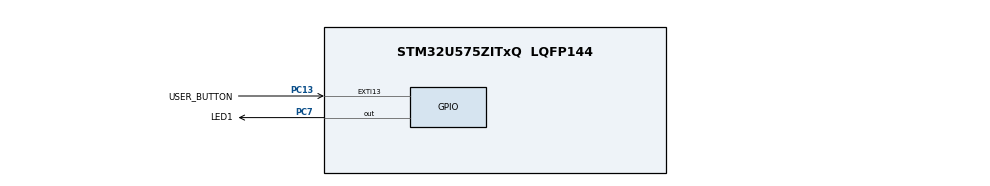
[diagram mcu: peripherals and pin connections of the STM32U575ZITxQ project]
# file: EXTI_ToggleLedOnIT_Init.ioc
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CORTEX_M33_NS.userName=CORTEX_M33
Mcu.Family=STM32U5
Mcu.Name=STM32U575ZITxQ
Mcu.Package=LQFP144
NVIC.EXTI13_IRQn=true\:0\:0\:false\:false\:true\:true\:true\:true
NVIC.PriorityGroup=NVIC_PRIORITYGROUP_4
PC13.GPIO_Label=USER_BUTTON
PC13.GPIO_ModeDefaultEXTI=GPIO_MODE_IT_FALLING
PC13.Signal=GPXTI13
PC7.GPIO_Label=LED1
PC7.Signal=GPIO_Output
PWR.PowerMode=PWR_SMPS_SUPPLY
ProjectManager.HeapSize=0x200
ProjectManager.StackSize=0x400
ProjectManager.TargetToolchain=EWARM V8.50
RCC.ADCFreq_Value=16000000
RCC.AHBFreq_Value=160000000
RCC.APB1Freq_Value=160000000
RCC.APB1TimFreq_Value=160000000
RCC.APB2Freq_Value=160000000
RCC.APB2TimFreq_Value=160000000
RCC.APB3Freq_Value=160000000
RCC.CortexFreq_Value=160000000
RCC.DACCLockSelectionVirtual=RCC_DAC1CLKSOURCE_LSI
RCC.DACCLockSelectionVirtualString=RCC_DAC1CLKSOURCE_LSI
RCC.EPOD_VALUE=4000000
RCC.HCLKFreq_Value=160000000
RCC.HSE_VALUE=16000000
RCC.HSI48_VALUE=48000000
RCC.HSI_VALUE=16000000
RCC.LSE_VALUE=32768
RCC.LSIDIV_VALUE=32000
RCC.MSI_VALUE=4000000
RCC.PLLN=80
RCC.SYSCLKFreq_VALUE=160000000
RCC.SYSCLKSource=RCC_SYSCLKSOURCE_PLLCLK
RCC.USBFreq_Value=48000000
RCC.VCOOutputFreq_Value=320000000
VP_ICACHE_VS_ICACHE.Mode=DirectMappedCache
VP_LPBAMQUEUE_VS_QUEUE.Mode=QUEUEMODE
VP_LPBAM_VS_SIG1.Mode=SmartRun
VP_LPBAM_VS_SIG4.Mode=LPDMA1
VP_PWR_VS_DBSignals.Mode=DisableDeadBatterySignals
VP_PWR_VS_LPOM.Mode=PowerOptimisation
VP_PWR_VS_SECSignals.Mode=Security/Privilege
board=custom

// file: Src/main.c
/* USER CODE BEGIN Header */
/**
  ******************************************************************************
  * @file    Examples_LL/EXTI/EXTI_ToggleLedOnIT_Init/Src/main.c
  * @author  MCD Application Team
  * @brief   This example describes how to configure the EXTI and use
  *          GPIOs using the STM32U5xx LL API to toggles the available
  *          users Leds on the board when User button is pressed.
  *          Peripheral initialization done using LL initialization function.
  ******************************************************************************
  * @attention
  *
  * Copyright (c) 2021 STMicroelectronics.
  * All rights reserved.
  *
  * This software is licensed under terms that can be found in the LICENSE file
  * in the root directory of this software component.
  * If no LICENSE file comes with this software, it is provided AS-IS.
  *
  ******************************************************************************
  */
/* USER CODE END Header */
#include "main.h"

void SystemClock_Config(void);
static void SystemPower_Config(void);
static void MX_GPIO_Init(void);
static void MX_ICACHE_Init(void);

int main(void)
{

  /* MCU Configuration--------------------------------------------------------*/

  /* Reset of all peripherals, Initializes the Flash interface and the Systick. */

  /* System interrupt init*/
  NVIC_SetPriorityGrouping(NVIC_PRIORITYGROUP_4);

  /* Enable PWR clock interface */

  LL_AHB3_GRP1_EnableClock(LL_AHB3_GRP1_PERIPH_PWR);

  /* Configure the System Power */
  SystemPower_Config();

  /* Configure the system clock */
  SystemClock_Config();

  /* Initialize all configured peripherals */
  MX_GPIO_Init();
  MX_ICACHE_Init();

  /* Infinite loop */
  while (1)
  {

  }
}

void SystemClock_Config(void)
{
  LL_FLASH_SetLatency(LL_FLASH_LATENCY_4);
  while(LL_FLASH_GetLatency()!= LL_FLASH_LATENCY_4)
  {
  }

  LL_PWR_SetRegulVoltageScaling(LL_PWR_REGU_VOLTAGE_SCALE1);
  while (LL_PWR_IsActiveFlag_VOS() == 0)
  {
  }
  LL_RCC_MSIS_Enable();

   /* Wait till MSIS is ready */
  while(LL_RCC_MSIS_IsReady() != 1)
  {
  }

  LL_RCC_MSI_EnableRangeSelection();
  LL_RCC_MSIS_SetRange(LL_RCC_MSISRANGE_4);
  LL_RCC_MSI_SetCalibTrimming(16, LL_RCC_MSI_OSCILLATOR_1);
  LL_RCC_PLL1_ConfigDomain_SYS(LL_RCC_PLL1SOURCE_MSIS, 1, 80, 2);
  LL_RCC_PLL1_EnableDomain_SYS();
  LL_RCC_SetPll1EPodPrescaler(LL_RCC_PLL1MBOOST_DIV_1);
  LL_RCC_PLL1_SetVCOInputRange(LL_RCC_PLLINPUTRANGE_4_8);
  LL_RCC_PLL1_Enable();

   /* Wait till PLL is ready */
  while(LL_RCC_PLL1_IsReady() != 1)
  {
  }

   /* Intermediate AHB prescaler 2 when target frequency clock is higher than 80 MHz */
  LL_RCC_SetAHBPrescaler(LL_RCC_SYSCLK_DIV_2);

  LL_RCC_SetSysClkSource(LL_RCC_SYS_CLKSOURCE_PLL1);

   /* Wait till System clock is ready */
  while(LL_RCC_GetSysClkSource() != LL_RCC_SYS_CLKSOURCE_STATUS_PLL1)
  {
  }

  /* Insure 1us transition state at intermediate medium speed clock*/
  for (__IO uint32_t i = (160 >> 1); i !=0; i--);

  LL_RCC_SetAHBPrescaler(LL_RCC_SYSCLK_DIV_1);
  LL_RCC_SetAPB1Prescaler(LL_RCC_APB1_DIV_1);
  LL_RCC_SetAPB2Prescaler(LL_RCC_APB2_DIV_1);
  LL_RCC_SetAPB3Prescaler(LL_RCC_APB3_DIV_1);

  LL_Init1msTick(160000000);

  LL_SetSystemCoreClock(160000000);
}

/**
  * @brief Power Configuration
  * @retval None
  */
static void SystemPower_Config(void)
{

  /*
   * Disable the internal Pull-Up in Dead Battery pins of UCPD peripheral
   */
  LL_PWR_DisableUCPDDeadBattery();

  /*
   * Switch to SMPS regulator instead of LDO
   */
  LL_PWR_SetRegulatorSupply(LL_PWR_SMPS_SUPPLY);

  while(LL_PWR_IsActiveFlag_REGULATOR()!=1)
  {
  }
}

static void MX_ICACHE_Init(void)
{

  /** Enable instruction cache in 1-way (direct mapped cache)
  */
  LL_ICACHE_SetMode(LL_ICACHE_1WAY);
  LL_ICACHE_Enable();

}

static void MX_GPIO_Init(void)
{
  LL_EXTI_InitTypeDef EXTI_InitStruct = {0};
  LL_GPIO_InitTypeDef GPIO_InitStruct = {0};

  /* GPIO Ports Clock Enable */
  LL_AHB2_GRP1_EnableClock(LL_AHB2_GRP1_PERIPH_GPIOC);

  /**/
  LL_GPIO_ResetOutputPin(LED1_GPIO_Port, LED1_Pin);

  /**/
  LL_EXTI_SetEXTISource(LL_EXTI_EXTI_PORTC, LL_EXTI_EXTI_LINE13);

  /**/
  EXTI_InitStruct.Line_0_31 = LL_EXTI_LINE_13;
  EXTI_InitStruct.LineCommand = ENABLE;
  EXTI_InitStruct.Mode = LL_EXTI_MODE_IT;
  EXTI_InitStruct.Trigger = LL_EXTI_TRIGGER_FALLING;
  LL_EXTI_Init(&EXTI_InitStruct);

  /**/
  LL_GPIO_SetPinPull(USER_BUTTON_GPIO_Port, USER_BUTTON_Pin, LL_GPIO_PULL_NO);

  /**/
  LL_GPIO_SetPinMode(USER_BUTTON_GPIO_Port, USER_BUTTON_Pin, LL_GPIO_MODE_INPUT);

  /**/
  GPIO_InitStruct.Pin = LED1_Pin;
  GPIO_InitStruct.Mode = LL_GPIO_MODE_OUTPUT;
  GPIO_InitStruct.Speed = LL_GPIO_SPEED_FREQ_LOW;
  GPIO_InitStruct.OutputType = LL_GPIO_OUTPUT_PUSHPULL;
  GPIO_InitStruct.Pull = LL_GPIO_PULL_NO;
  LL_GPIO_Init(LED1_GPIO_Port, &GPIO_InitStruct);

  /* EXTI interrupt init*/
  NVIC_SetPriority(EXTI13_IRQn, NVIC_EncodePriority(NVIC_GetPriorityGrouping(),0, 0));
  NVIC_EnableIRQ(EXTI13_IRQn);

}

/* USER CODE BEGIN 4 */

/******************************************************************************/
/*   USER IRQ HANDLER TREATMENT                                               */
/******************************************************************************/
/**
  * @brief  Function to manage IRQ Handler
  * @param  None
  * @retval None
  */
void UserButton_Callback(void)
{
  LL_GPIO_TogglePin(LED1_GPIO_Port, LED1_Pin);
}

/* USER CODE END 4 */

void Error_Handler(void)
{
}
